# BearlyML register map
Vendor: UCB-BAR; Series: EE194/290C Sp22; File version: 2022.0.0
64-bit SoC for machine-learning workloads
CPU: Rocket rv64imafc, little endian, no MPU, no FPU, vendor SysTick, 1 interrupt priority bits
Registers are 32-bit, read-write, reset 0x0 unless marked. A register's access mark holds for its fields unless they carry their own. Offsets are from the block's base; lines under a group give offsets from that group; [hi:lo] are bit positions; {n}, {i} and the like mark numbered series; 'fields as' and 'values as' point back to an identical list; <NAME> marks a mode.

## Memory map
0x00000000 DEBUG_CONTROLLER size 0x400
0x00003000 ERROR_DEVICE size 0x400
0x00003000 BOOTSEL size 0x400 — Boot mode selection
0x00100000 PRCI size 0x1000 — Power, Reset, Clock, Interrupt.
0x02000000 CLINT size 0x10000 — Core Local Interruptor.
0x0C000000 PLIC size 0x200008 — Platform-Level Interrupt Controller.
0x10012000 GPIO0 size 0x1000 — General purpose input/output controller.
0x1001A000 UART0 size 0x1000 — Universal Asynchronous Receiver/Transmitter.
0x10020000 QSPI0 size 0x1000 — Quad Serial Peripheral Interface.
0x10024000 I2C0 size 0x1000 — Inter-Integrated Circuit.

## Interrupts
3 UART0_IRQ (UART0)
5 QSPI0_IRQ (QSPI0)
{n+8} GPIO_{n}_IRQ (GPIO0) (n=0..31)
52 I2C_IRQ (I2C0)

## BOOTSEL — Boot mode selection
Base 0x00003000
0x00 BOOTSEL — Boot mode selection
  [2:0] BOOTSEL

## PRCI — Power, Reset, Clock, Interrupt.
Base 0x00100000
{0x0+4i} TILE[{i}]_RESET (i=0..4)
  [0] RESET
{0x1008+4i} TILE[{i}]_CLKGATE (i=0..4) — Tile Clock Gating.
  [0] CLKGATE
0x2000 CLK_SEL — Clock Select.
  [0] CLK_SEL
0x2004 DEBUG_CLK_EN — Debug Clock Enable.
  [0] DEBUG_CLK_EN
0x2008 DEBUG_CLK_SEL — Debug Clock Select.
  [1:0] DEBUG_CLK_SEL
0x200C DEBUG_CLK_DIV — Debug Clock Divisor.
  [7:0] DEBUG_CLK_SEL
0x3000 FBUS_CLK_DIV — FBus Clock Divisor.
  [7:0] FBUS_CLK_DIV
0x3004 UNCORE_CLK_DIV — Uncore Area Clock Divisor.
  [7:0] FBUS_CLK_DIV
{0x3008+4i} TILE[{i}]_CLK_DIV (i=0..4) — Tile Clock Divisor.
  [7:0] DIV

## CLINT — Core Local Interruptor.
Base 0x02000000
{0x0+4i} MSIP[{i}] (i=0..4) — Machine Software Interrupt Pending Register.
  [0] MSIP
0x4000 MTIMECMP_LO — Machine Timer Compare Register Low.
0x4004 MTIMECMP_HI — Machine Timer Compare Register High.
0xBFF8 MTIME_LO — Machine Timer Register Low.
0xBFFC MTIME_HI — Machine Timer Register High.

## PLIC — Platform-Level Interrupt Controller.
Base 0x0C000000
{0x0+4i} PRIORITY[{i}] (i=0..51) — PLIC Interrupt Priority Register.
  [2:0] PRIORITY
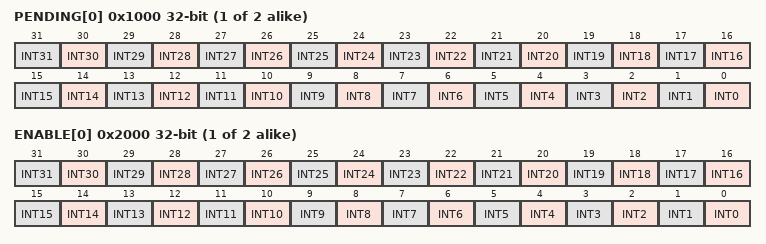
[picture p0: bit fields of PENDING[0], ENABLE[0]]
{0x1000+4i} PENDING[{i}] (i=0..1) — PLIC Interrupt Pending Register.
  [n] INT{n} (n=0..31)
{0x2000+4i} ENABLE[{i}] (i=0..1) — PLIC Interrupt Enable Register.
  [n] INT{n} (n=0..31)
0x200000 THRESHOLD — PLIC Interrupt Priority Threshold Register.
  [2:0] THRESHOLD
0x200004 CLAIM ro — PLIC Claim Register.
0x200004 COMPLETE wo — PLIC Complete Register.

## GPIO0 — General purpose input/output controller.
Base 0x10012000
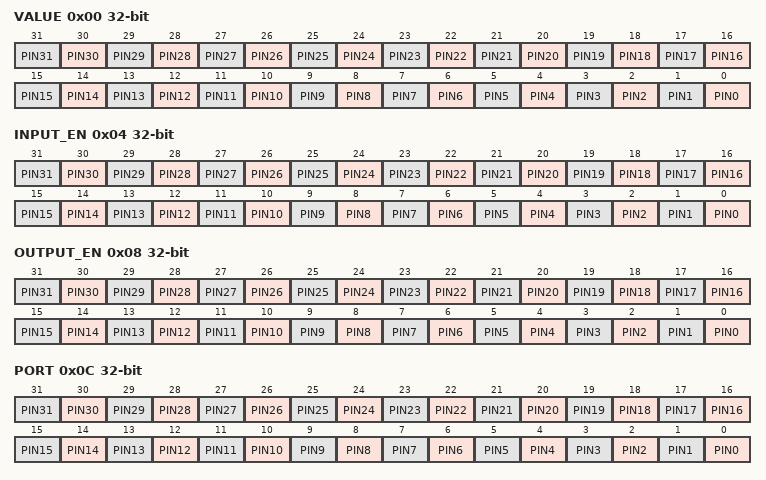
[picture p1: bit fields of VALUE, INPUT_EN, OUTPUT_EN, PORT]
0x00 VALUE — Pin value.
  [n] PIN{n} (n=0..31)
0x04 INPUT_EN — Pin input enable.
  [n] PIN{n} (n=0..31)
0x08 OUTPUT_EN — Pin output enable.
  [n] PIN{n} (n=0..31)
0x0C PORT — Output port value.
  [n] PIN{n} (n=0..31)
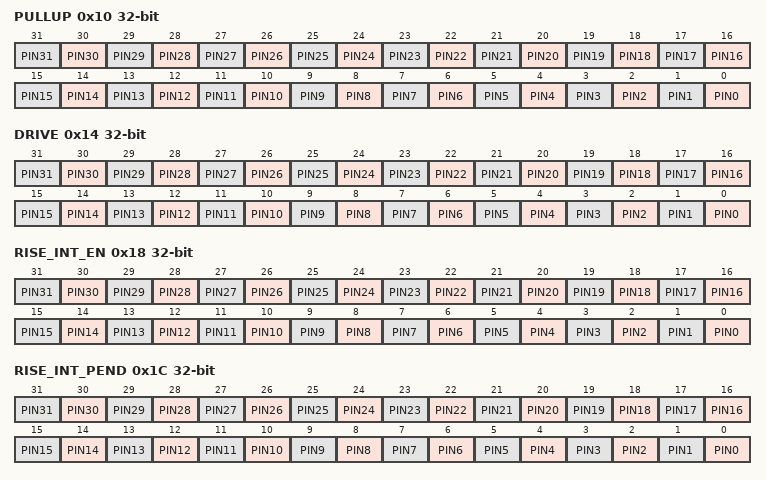
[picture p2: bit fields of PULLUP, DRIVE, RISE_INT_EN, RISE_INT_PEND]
0x10 PULLUP — Internal Pull-Up enable.
  [n] PIN{n} (n=0..31)
0x14 DRIVE — Drive Strength.
  [n] PIN{n} (n=0..31)
0x18 RISE_INT_EN — Rise interrupt enable.
  [n] PIN{n} (n=0..31)
0x1C RISE_INT_PEND — Rise interrupt pending.
  [n] PIN{n} (n=0..31)
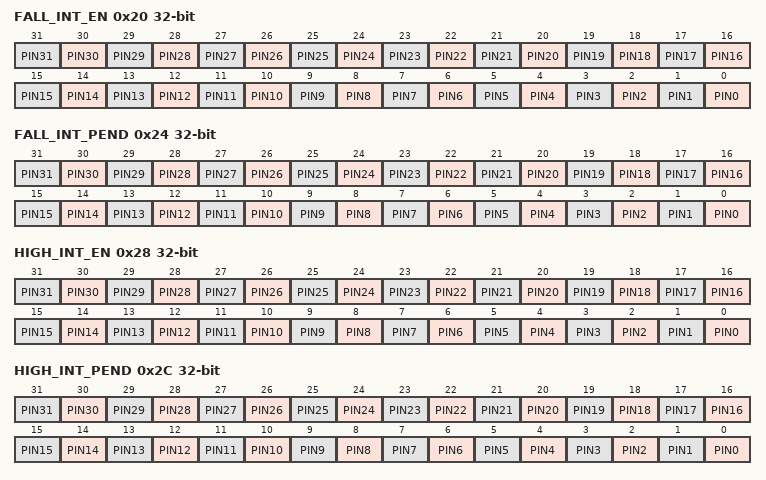
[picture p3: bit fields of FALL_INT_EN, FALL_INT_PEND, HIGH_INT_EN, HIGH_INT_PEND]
0x20 FALL_INT_EN — Fall interrupt enable.
  [n] PIN{n} (n=0..31)
0x24 FALL_INT_PEND — Fall interrupt pending.
  [n] PIN{n} (n=0..31)
0x28 HIGH_INT_EN — High interrupt enable.
  [n] PIN{n} (n=0..31)
0x2C HIGH_INT_PEND — High interrupt pending.
  [n] PIN{n} (n=0..31)
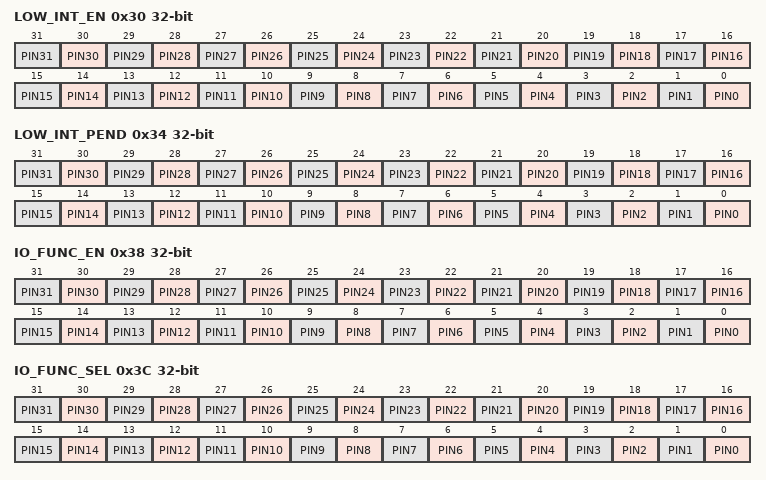
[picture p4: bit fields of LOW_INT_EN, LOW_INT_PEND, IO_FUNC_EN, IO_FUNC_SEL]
0x30 LOW_INT_EN — Low interrupt enable.
  [n] PIN{n} (n=0..31)
0x34 LOW_INT_PEND — Low interrupt pending.
  [n] PIN{n} (n=0..31)
0x38 IO_FUNC_EN — HW I/O function enable.
  [n] PIN{n} (n=0..31)
0x3C IO_FUNC_SEL — HW I/O function select.
  [n] PIN{n} (n=0..31)
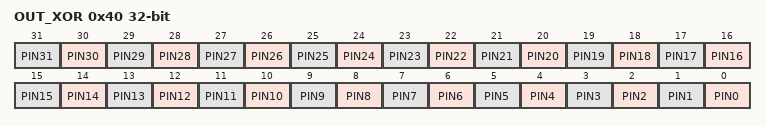
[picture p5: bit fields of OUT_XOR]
0x40 OUT_XOR — Output XOR (invert).
  [n] PIN{n} (n=0..31)

## UART0 — Universal Asynchronous Receiver/Transmitter.
Base 0x1001A000
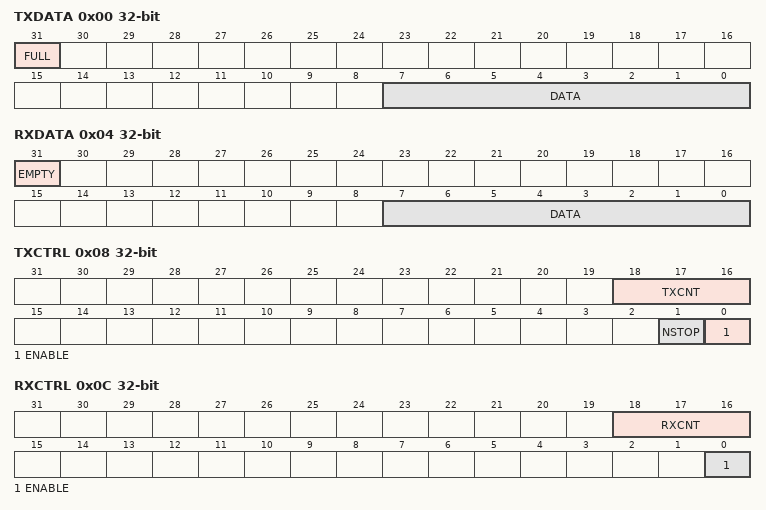
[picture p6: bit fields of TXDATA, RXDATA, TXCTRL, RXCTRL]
0x00 TXDATA — Transmit Data Register.
  [31] FULL, [7:0] DATA
0x04 RXDATA ro — Receive Data Register.
  [31] EMPTY, [7:0] DATA
0x08 TXCTRL — Transmit Control Register.
  [18:16] TXCNT, [1] NSTOP, [0] ENABLE
0x0C RXCTRL — Receive Control Register.
  [18:16] RXCNT, [0] ENABLE
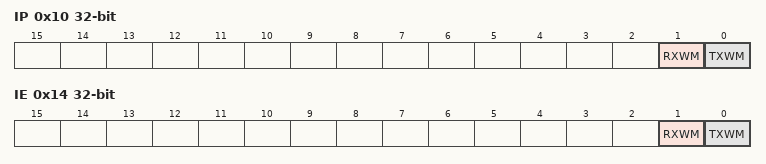
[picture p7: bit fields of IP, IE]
0x10 IP — Interrupt Pending Register.
  [1] RXWM, [0] TXWM
0x14 IE — Interrupt Enable Register.
  [1] RXWM, [0] TXWM
0x18 DIV — Baud Rate Divisor Register (BAUD = Fin / (DIV + 1)).
  [15:0] DIV

## QSPI0 — Quad Serial Peripheral Interface.
Base 0x10020000
0x00 SCKDIV — Serial Clock Divisor Register.
  [11:0] SCALE
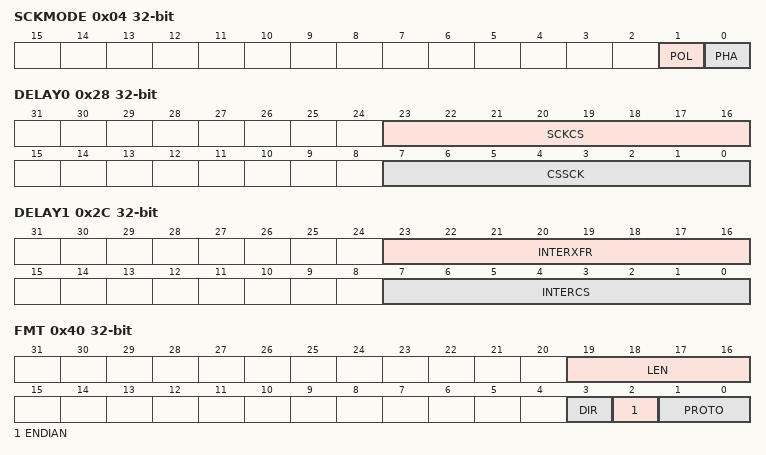
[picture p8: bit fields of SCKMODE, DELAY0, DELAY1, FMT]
0x04 SCKMODE — Serial Clock Mode Register.
  [1] POL — Serial Clock Polarity
    0=Inactive state of SCK is logical 0; 1=Inactive state of SCK is logical 1
  [0] PHA — Serial Clock Phase
    0=Data is sampled on the leading edge of SCK and shifted on the trailing edge of SCK; 1=Data is shifted on the leading edge of SCK and sampled on the trailing edge of SCK
0x10 CSID — Chip Select ID Register.
0x14 CSDEF — Chip Select Default Register.
0x18 CSMODE — Chip Select Mode Register.
  [1:0] MODE
    0=AUTO (Assert/de-assert CS at the beginning/end of each frame.); 2=HOLD (Keep CS continuously asserted after the initial frame.); 3=OFF (Disable hardware control of the CS pin.)
0x28 DELAY0 — Delay Control Register 0.
  [23:16] SCKCS, [7:0] CSSCK
0x2C DELAY1 — Delay Control Register 1.
  [23:16] INTERXFR, [7:0] INTERCS
0x40 FMT — Frame Format Register.
  [19:16] LEN
  [3] DIR
    0=RX (For dual and quad protocols, the DQ pins are tri-stated. For the single protocol, the DQ0 pin is driven with the transmit data as normal.); 1=TX (The receive FIFO is not populated.)
  [2] ENDIAN
    0=MSB_First (Tansmit most-significant bit first.); 1=LSB_First (Transmit least-significant bit first.)
  [1:0] PROTO
    0=Single (Data Pins: DQ0 (MOSI), DQ1 (MISO).); 1=Dual (Data Pins: DQ0, DQ1.); 2=Quad (Data Pins: DQ0, DQ1, DQ2, DQ3.)
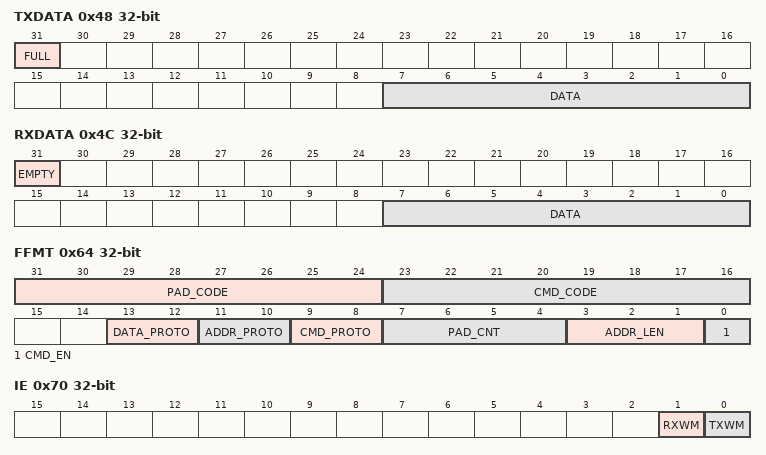
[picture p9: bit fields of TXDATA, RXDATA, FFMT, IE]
0x48 TXDATA — Transmit Data Register.
  [31] FULL, [7:0] DATA
0x4C RXDATA — Receive Data Register.
  [31] EMPTY, [7:0] DATA
0x50 TXMARK — Transmit Watermark Register.
  [2:0] TXMARK
0x54 RXMARK — Receive Watermark Register.
  [2:0] RXMARK
0x60 FCTRL — SPI Flash Interface Control Register.
  [0] ENABLE
0x64 FFMT — SPI Flash Instruction Format Register.
  [31:24] PAD_CODE, [23:16] CMD_CODE, [13:12] DATA_PROTO, [11:10] ADDR_PROTO, [9:8] CMD_PROTO, [7:4] PAD_CNT, [3:1] ADDR_LEN, [0] CMD_EN
0x70 IE — SPI Interrupt Enable Register.
  [1] RXWM, [0] TXWM
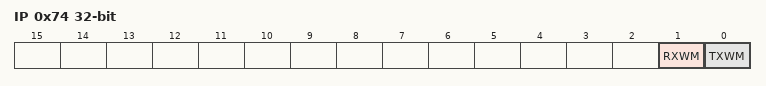
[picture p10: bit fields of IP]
0x74 IP — SPI Interrupt Pending Register.
  [1] RXWM, [0] TXWM

## I2C0 — Inter-Integrated Circuit.
Base 0x10024000
0x00 PRESCAL_LO — I2C Prescaler Low Register.
  [7:0] PRESCAL_LO
0x04 PRESCAL_HI — I2C Prescaler High Register.
  [7:0] PRESCAL_HI
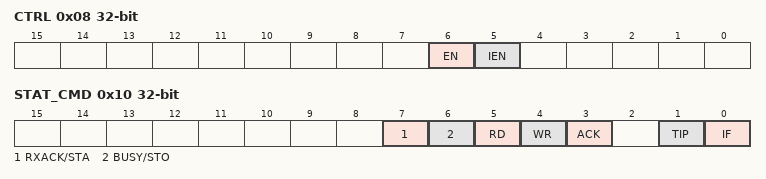
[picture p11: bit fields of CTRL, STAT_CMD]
0x08 CTRL — I2C Control Register.
  [6] EN, [5] IEN
0x0C DATA — I2C Data Register.
  [7:0] DATA
0x10 STAT_CMD — I2C Status Command Register.
  [7] RXACK/STA, [6] BUSY/STO, [5] RD, [4] WR, [3] ACK, [1] TIP, [0] IF
